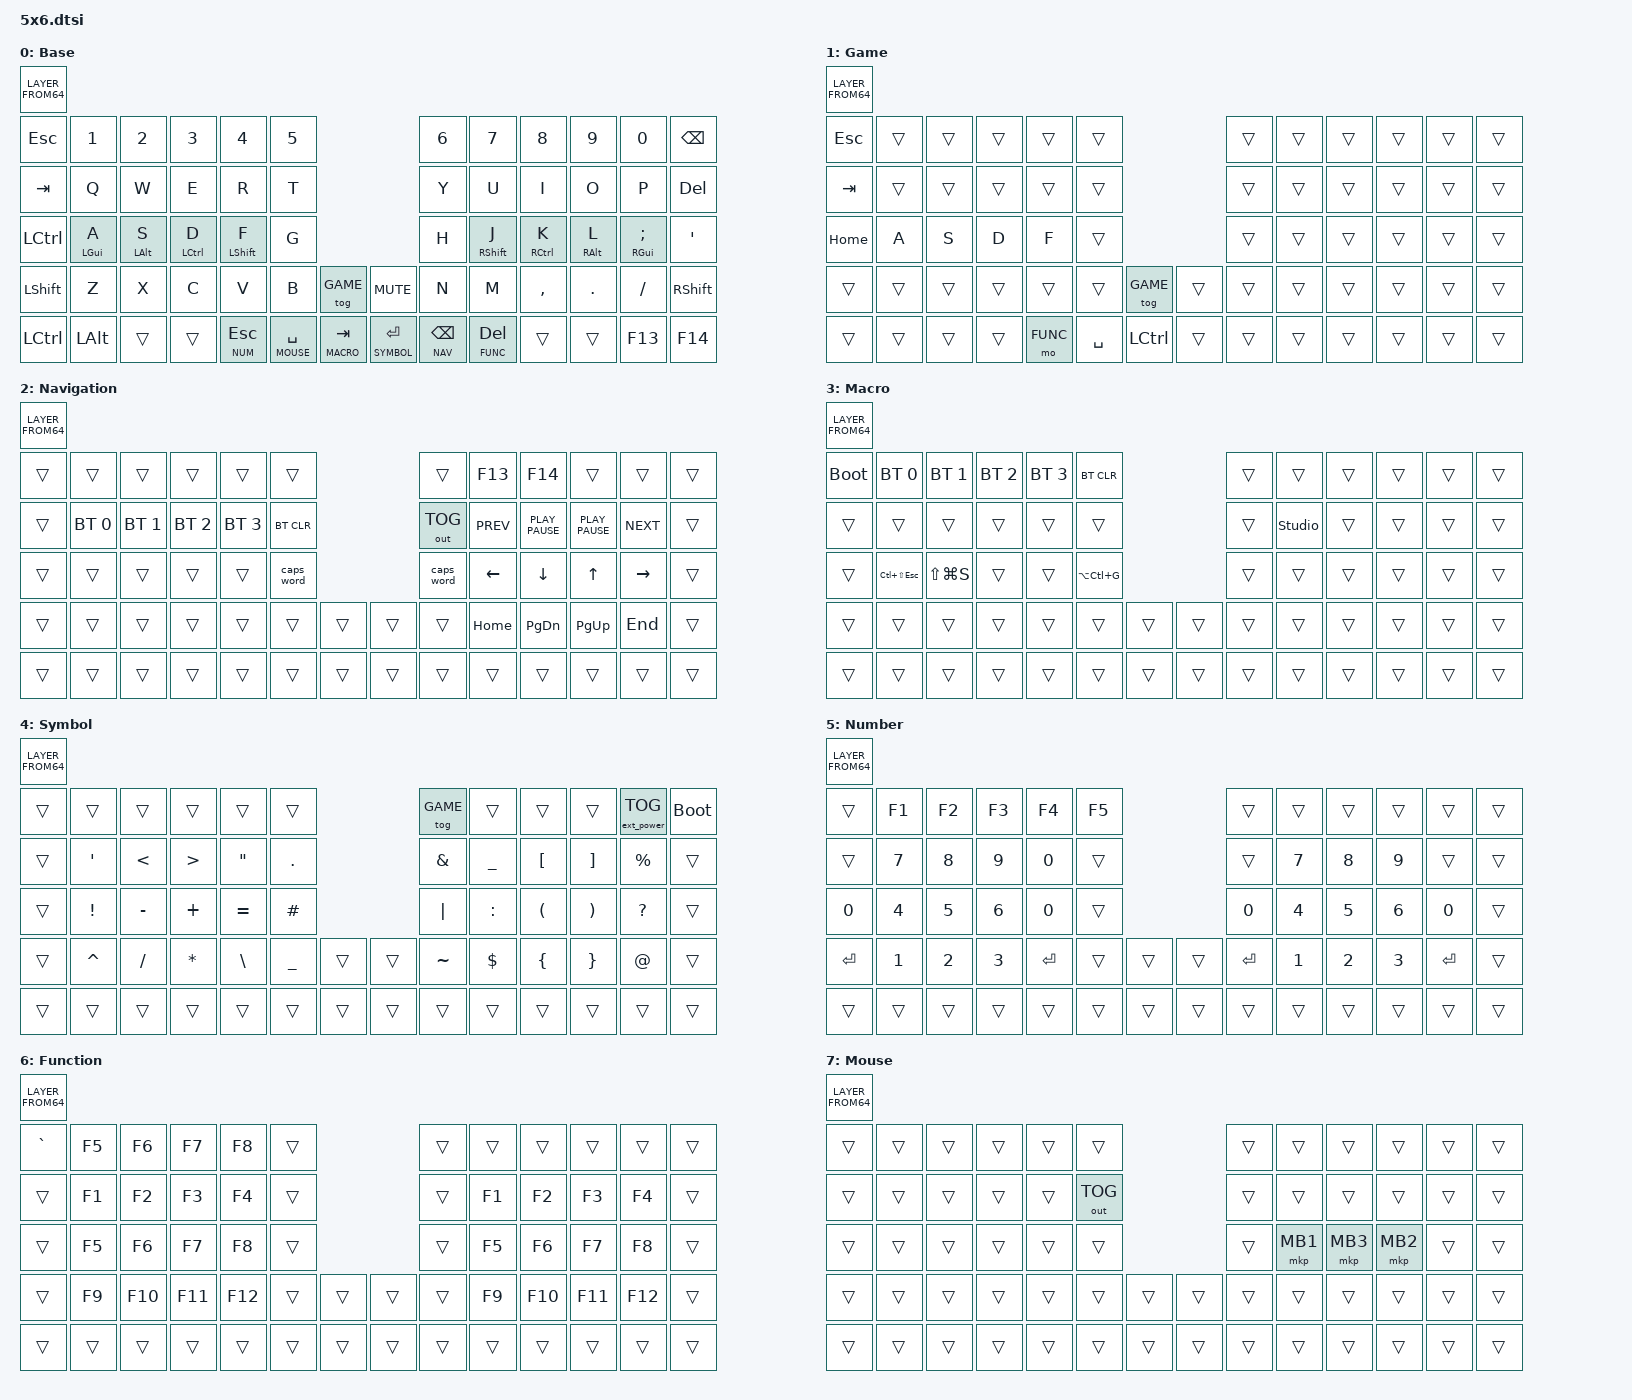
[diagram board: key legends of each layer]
// ZMK includes
#include <behaviors.dtsi>
#include <dt-bindings/zmk/bt.h>
#include <dt-bindings/zmk/ext_power.h>
#include <dt-bindings/zmk/keys.h>
#include <dt-bindings/zmk/pointing.h>
#include <dt-bindings/zmk/outputs.h>

#define ___ &trans
#define BASE 0
#define GAME 1
#define NAV 2
#define MACRO 3
#define SYMBOL 4
#define NUM 5
#define FUNC 6
#define MOUSE 7

/ {
    behaviors {
        hrm: hrm {
            label = "hrm";
            compatible = "zmk,behavior-hold-tap";
            #binding-cells = <2>;
            flavor = "balanced";
            tapping-term-ms = <280>;
            quick-tap-ms = <125>;
            global-quick-tap;
            bindings = <&kp>, <&kp>;
        };
    };

    sensors { triggers-per-rotation = <20>; };
};

/ {
    keymap {
        compatible = "zmk,keymap";

        default_layer {
            label = "Base";
            bindings = < LAYER_FROM64( \
&kp ESCAPE,  &kp N1,       &kp N2,       &kp N3,        &kp N4,             &kp N5,                                          &kp N6,             &kp N7,              &kp N8,        &kp N9,       &kp N0,          &kp BACKSPACE,
&kp TAB,     &kp Q,        &kp W,        &kp E,         &kp R,              &kp T,                                           &kp Y,              &kp U,               &kp I,         &kp O,        &kp P,           &kp DEL,
&kp LCTRL,   &hrm LGUI A,  &hrm LALT S,  &hrm LCTRL D,  &hrm LEFT_SHIFT F,  &kp G,                                           &kp H,              &hrm RIGHT_SHIFT J,  &hrm RCTRL K,  &hrm RALT L,  &hrm RGUI SEMI,  &kp SQT,
&kp LSHFT,   &kp Z,        &kp X,        &kp C,         &kp V,              &kp B,          &tog GAME,      &kp C_MUTE,      &kp N,              &kp M,               &kp COMMA,     &kp DOT,      &kp FSLH,        &kp RSHFT,
&kp LCTRL,   &kp LALT,     &trans,       &trans,        &lt NUM ESCAPE,     &lt MOUSE SPACE,&lt MACRO TAB,  &lt SYMBOL ENTER,&lt NAV BACKSPACE,  &lt FUNC DEL,        &trans,        &trans,       &kp F13,         &kp F14
            )>;

            sensor-bindings = <&inc_dec_kp LC(Y) LC(Z) &inc_dec_kp C_VOLUME_UP C_VOL_DN>;
        };

        game {
            label = "Game";
            bindings = < LAYER_FROM64( \
&kp ESCAPE,  &trans,  &trans,  &trans,  &trans,    &trans,                        &trans,  &trans,  &trans,  &trans,  &trans,  &trans,
&kp TAB,     &trans,  &trans,  &trans,  &trans,    &trans,                        &trans,  &trans,  &trans,  &trans,  &trans,  &trans,
&kp HOME,    &kp A,   &kp S,   &kp D,   &kp F,     &trans,                        &trans,  &trans,  &trans,  &trans,  &trans,  &trans,
&trans,      &trans,  &trans,  &trans,  &trans,    &trans,   &tog GAME,  &trans,  &trans,  &trans,  &trans,  &trans,  &trans,  &trans,
&trans,      &trans,  &trans,  &trans,  &mo FUNC,  &kp SPACE,&kp LCTRL,  &trans,  &trans,  &trans,  &trans,  &trans,  &trans,  &trans
            )>;
        };

        nav {
            label = "Navigation";
            bindings = < LAYER_FROM64( \
&trans,  &trans,        &trans,         &trans,        &trans,        &trans,                        &trans,      &kp F13,     &kp F14,           &trans,            &trans,      &trans,
&trans,  &bt BT_SEL 0,  &bt BT_SEL 1,   &bt BT_SEL 2,  &bt BT_SEL 3,  &bt BT_CLR,                    &out OUT_TOG,&kp K_PREV,  &kp K_PLAY_PAUSE,  &kp K_PLAY_PAUSE,  &kp K_NEXT,  &trans,
&trans,  &trans,        &trans,         &trans,        &trans,        &caps_word,                    &caps_word,  &kp LEFT,    &kp DOWN,          &kp UP,            &kp RIGHT,   &trans,
&trans,  &trans,        &trans,         &trans,        &trans,        &trans,      &trans,  &trans,  &trans,      &kp HOME,    &kp PG_DN,         &kp PG_UP,         &kp END,     &trans,
&trans,  &trans,        &trans,         &trans,        &trans,        &trans,      &trans,  &trans,  &trans,      &trans,      &trans,            &trans,            &trans,      &trans
            )>;
        };

        macro {
            label = "Macro";
            bindings = < LAYER_FROM64( \
&bootloader,  &bt BT_SEL 0,        &bt BT_SEL 1,   &bt BT_SEL 2,  &bt BT_SEL 3,  &bt BT_CLR,                &trans,  &trans,          &trans,  &trans,  &trans,  &trans,
&trans,       &trans,              &trans,         &trans,        &trans,        &trans,                    &trans,  &studio_unlock,  &trans,  &trans,  &trans,  &trans,
&trans,       &kp LC(LS(ESCAPE)),  &kp LS(LG(S)),  &trans,        &trans,        &kp LA(LC(G)),             &trans,  &trans,          &trans,  &trans,  &trans,  &trans,
&trans,       &trans,              &trans,         &trans,        &trans,        &trans,  &trans,  &trans,  &trans,  &trans,          &trans,  &trans,  &trans,  &trans,
&trans,       &trans,              &trans,         &trans,        &trans,        &trans,  &trans,  &trans,  &trans,  &trans,          &trans,  &trans,  &trans,  &trans
            )>;
        };

        symbol {
            label = "Symbol";
            bindings = < LAYER_FROM64( \
&trans,  &trans,            &trans,         &trans,            &trans,             &trans,                        &tog GAME,  &trans,      &trans,                &trans,                 &ext_power EP_TOG,  &bootloader,
&trans,  &kp SINGLE_QUOTE,  &kp LESS_THAN,  &kp GREATER_THAN,  &kp DOUBLE_QUOTES,  &kp PERIOD,                    &kp AMPS,   &kp UNDER,   &kp LEFT_BRACKET,      &kp RIGHT_BRACKET,      &kp PERCENT,        &trans,
&trans,  &kp EXCL,          &kp MINUS,      &kp PLUS,          &kp EQUAL,          &kp HASH,                      &kp PIPE,   &kp COLON,   &kp LEFT_PARENTHESIS,  &kp RIGHT_PARENTHESIS,  &kp QUESTION,       &trans,
&trans,  &kp CARET,         &kp SLASH,      &kp STAR,          &kp BACKSLASH,      &kp UNDER,   &trans,  &trans,  &kp TILDE,  &kp DOLLAR,  &kp LEFT_BRACE,        &kp RIGHT_BRACE,        &kp AT,             &trans,
&trans,  &trans,            &trans,         &trans,            &trans,             &trans,      &trans,  &trans,  &trans,     &trans,      &trans,                &trans,                 &trans,             &trans
            )>;
        };

        number {
            label = "Number";
            bindings = < LAYER_FROM64( \
&trans,        &kp F1,        &kp F2,        &kp F3,        &kp F4,        &kp F5,                    &trans,        &trans,        &trans,        &trans,        &trans,        &trans,
&trans,        &kp NUMBER_7,  &kp NUMBER_8,  &kp NUMBER_9,  &kp NUMBER_0,  &trans,                    &trans,        &kp NUMBER_7,  &kp NUMBER_8,  &kp NUMBER_9,  &trans,        &trans,
&kp NUMBER_0,  &kp NUMBER_4,  &kp NUMBER_5,  &kp NUMBER_6,  &kp NUMBER_0,  &trans,                    &kp NUMBER_0,  &kp NUMBER_4,  &kp NUMBER_5,  &kp NUMBER_6,  &kp NUMBER_0,  &trans,
&kp ENTER,     &kp NUMBER_1,  &kp NUMBER_2,  &kp NUMBER_3,  &kp ENTER,     &trans,  &trans,  &trans,  &kp ENTER,     &kp NUMBER_1,  &kp NUMBER_2,  &kp NUMBER_3,  &kp ENTER,     &trans,
&trans,        &trans,        &trans,        &trans,        &trans,        &trans,  &trans,  &trans,  &trans,        &trans,        &trans,        &trans,        &trans,        &trans
            )>;
        };

        function {
            label = "Function";
            bindings = < LAYER_FROM64( \
&kp GRAVE, &kp F5,  &kp F6,   &kp F7,   &kp F8,   &trans,                    &trans,  &trans,  &trans,   &trans,   &trans,   &trans,
&trans,    &kp F1,  &kp F2,   &kp F3,   &kp F4,   &trans,                    &trans,  &kp F1,  &kp F2,   &kp F3,   &kp F4,   &trans,
&trans,    &kp F5,  &kp F6,   &kp F7,   &kp F8,   &trans,                    &trans,  &kp F5,  &kp F6,   &kp F7,   &kp F8,   &trans,
&trans,    &kp F9,  &kp F10,  &kp F11,  &kp F12,  &trans,  &trans,  &trans,  &trans,  &kp F9,  &kp F10,  &kp F11,  &kp F12,  &trans,
&trans,    &trans,  &trans,   &trans,   &trans,   &trans,  &trans,  &trans,  &trans,  &trans,  &trans,   &trans,   &trans,   &trans
            )>;
        };

        mouse {
            label = "Mouse";
            bindings = < LAYER_FROM64( \
&trans,    &trans,  &trans,   &trans,   &trans,   &trans,                    &trans,  &trans,   &trans,   &trans,   &trans,   &trans,
&trans,    &trans,  &trans,   &trans,   &trans,   &out OUT_TOG,              &trans,  &trans,   &trans,   &trans,   &trans,   &trans,
&trans,    &trans,  &trans,   &trans,   &trans,   &trans,                    &trans,  &mkp MB1, &mkp MB3, &mkp MB2,   &trans,   &trans,
&trans,    &trans,  &trans,   &trans,   &trans,   &trans,  &trans,  &trans,  &trans,  &trans,   &trans,   &trans,   &trans,   &trans,
&trans,    &trans,  &trans,   &trans,   &trans,   &trans,  &trans,  &trans,  &trans,  &trans,   &trans,   &trans,   &trans,   &trans
            )>;
        };
    };
};
